# rCSL_sata_001 register map
Vendor: Texas Instruments
Registers are 32-bit, access not given, reset 0x0 unless marked. A register's access mark holds for its fields unless they carry their own. Offsets are as the file gives them; [hi:lo] are bit positions.

## SATA (part 2 of 2) — SATA Interface Controller
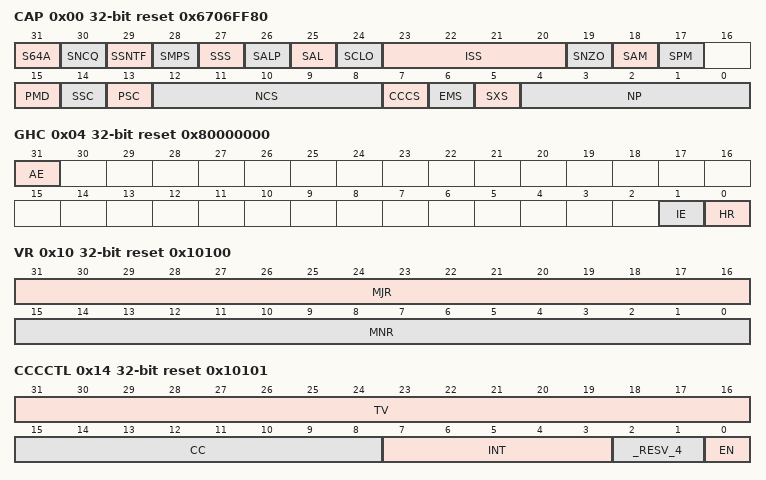
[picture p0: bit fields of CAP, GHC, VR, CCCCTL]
0x00 CAP reset 0x6706FF80 (reset mask 0xFF0FFFFF) — HBA Capabilities Register
  [31] S64A ro — Indicates the resolution of the addressing supported 32-bit or 64-bit. This bit field should always display 0 since only 32-bit addressing is supported. 0: 32-bit addressing is selected. 1: 64-bit addressing selected.
  [30] SNCQ ro — Indicates the support for Native Command Queueing. This bit field should always display 1 since Native Command Queueing is supported. 0: Native Command is not supported. 1: Native Command Queueing is supported by handlind DMA Setup FIS Natively.
  [29] SSNTF ro — Indicates Register SATASS support for SNotification. This bit field should always display 1 since SATASS suports POSNTF (SNotification) register and its asscoited functionality. 0: SNotification register and its associated functionality is not supported. 1: SNotification register and its associated functionality is supported.
  [28] SMPS rw — Indicates existence of a mechanical swich. Mechanical presence switch detection is supported by the SATASS. However, the visibility of the support for this switch is controlled by the Firmware with a one time write capability during power up time. Then after, this bit fied is read only. Firmware writes the following right after power-up: 0: Mechanical Switch is not present and no detecition capability is available. 1: Mechanical Switch is present and detection capability is available.
  [27] SSS rw — Indicates the supports for Staggered Spin-Up. Staggered Spin-Up is supported by the SATASS. However, the visibility of the support for this capability is controlled by the Firmware with a one time write capability during power up time.Then after, this bit field, is read-only. Firmware writes the following right after power-up: 0: Staggered Spin-Up is not supported. 1: Staggered Spin-Up is supported.
  [26] SALP ro — Indicates the support for Aggressive Link Power Manangemet (ALPM). This value should always display 1. 0: SATASS does not support ALPM. 1: SATASS supports ALPM.
  [25] SAL ro — Indicates the presence of activity. 0: No Activity 1: Activity is detected.
  [24] SCLO ro — Indicates the Support for the Command List Override. SATASS supports the P#CMD.CLO bit functionality for Port Multiplier Devices's Enumeration.
  [23:20] ISS ro — Indicates the maximum interface speed supported: Generation 1 which is 1.5 Gbps and Generation 2 which is 3.0 Gbps. 0: Reserved 1: 1.5 Gbps (Gen1) 2: 3.0 Gbps (Gen2) 3-15: Reserved
  [19] SNZO ro — Indicate the support the Non-Zero DMA Offsets. 0: Not Supported. 1: Non-Zero Offset supported.
  [18] SAM ro — Indicates whether the Legacy Task File Register Interface or AHCI interface supported. No support for Legacy Mode. 0: Task File Register Interface supported. 1: AHCI interface supported.
  [17] SPM ro — Indicates whether the support for Port Multiplier. 0: Command-based Switching Port Multiplier is not supported. 1: Command-based Switching Port Multiplier on any of its ports supported.
  [15] PMD ro — Indicates whether the support for PIO Multiple DRQ block data transfer is supported or not. 0: PIO Multiple DRQ block data transfer not supported. 1: PIO Multiple DRQ block data transfer supported.
  [14] SSC ro — Indicates whether the transition for the Slumber State Power Management Capability is supported or not. 0: Does not support the transition to the SLUMBER power state. 1: SATSS supports for the transition to the SLUMBER power state.
  [13] PSC ro — Indicates whether the transition capability to Partial power state management. 0: Does not support the transition to the PARTIAL power state. 1: SATSS supports the transition to the PARTIAL power state.
  [12:8] NCS ro — Indicates the number of command slots supported. The value encoded here is one less than the actual value, i.e. value of 0x1F implies the support for the maximum number of command slots per port, which is 32.
  [7] CCCS ro — Indicates if the Command Coalescing is supported or not. 0: Command Coalescing not supported. 1: Command Coalescing supported.
  [6] EMS ro — Indicates the support for Enclosure Management. 0: Enclosure Management not supported. 1: Enclosure Management is supported.
  [5] SXS ro — Indicates whether the support for External SATA is accomdated or not. 0: No External SATA is supported. 1: External SATA is supported.
  [4:0] NP ro — Indicates the number of SATA ports supported. Value encoded here is one less the actual value, i.e., value of 0 implies the support for a single 1 Port.
0x04 GHC reset 0x80000000 — Provides global functions for the SATASS
  [31] AE ro — Indicates the communication mechanism with the HBA being Legacy mode or Advanced Host Controller Interface mode. Since Legacy mode is not supported, the mode of communication is AHCI mode all the time, i.e, this bit field is always set. 0: AHCI is not enabled 1: AHCI is enabled.
  [1] IE rw — Global Interrupt Enable/Disable bit filed. This field is affected by HBA reset. 0: Interrupt is not Enabled globally. 1: Interrupt is Enabled globally.
  [0] HR wo — Host Bus Adaptor (HBA) reset. Only Write of '1' supported. When HBA is finished with the reset, it will clear this bit field to '0'. Write of '0' has no effect.
0x08 IS — Interrupt Status Register of a Port
  [0] IPS rw — Interrupt Pending Status for port 0. 0: No Pending Port 0 Interrupt. 1: Interrupt Pending for Port 0.
0x0C PI — Ports Implemented Register
  [0] PI ro — This bit field should be intialized by the Firmware, after power up, by writing '1' to it, since only one port is available and that is the minimum amount of port that should remain available. After the write by the Firmware, this bit field is read-only there after.
0x10 VR ro reset 0x10100 — This register indicates the version of the Synopsys AHCI core embedded in the SATASS.
  [31:16] MJR — Major Revision Number
  [15:0] MNR — Minor Revision Number
0x14 CCCCTL reset 0x10101 — This register is used to configure the command completion coalescing (CCC) feature for the SATASS core. It is reset on Global reset.
  [31:16] TV rw — Time out value recorded in 1ms interval. S/W should initialize/load this value prior to enabling CCC. Can only write to this field if CCCCTL.EN==0 (i.e. CCC is disabled). If not it is read only. The HBA will signal a CCC interrupt when the time out value entered has decremented to 0. A copy of this value is used within the HBA and this field value will not change. A value of 0x0000 is reserved and should not be used.
  [15:8] CC rw — Command Completions: This field specifies the number of command completions that are necessary to cause a CCC interrupt. S/W should initialize/load this value prior to enabling CCC. Can only write to this field if CCCCTL.EN==0 (i.e. CCC is disabled). If not it is read only. A value of 0x0000 is reserved and should not be used.
  [7:3] INT ro — This field specifies the interrupt used by the CCC feature and is meaningful in identifying the HBA port that has interrupt pending. Since the number or HBA port supported is one and the supported HBA port is port 0, this field is either 0 or 1. 0: No CCC feature interrupt pending. 1: CCC feature Interrupt is pending for HBA Port 0.
  [2:1] _RESV_4 — Resevered (access N)
  [0] EN rw — Enables/Disables CCC feature (note that some of the CCC fields require initialization prior to enabling CCC). 0: CCC feature is Disabled (no CCC interrupt will be generated). 1: CCC feature is Enabled (CCC interrupt may be generated based on timeout or command completion conditions).
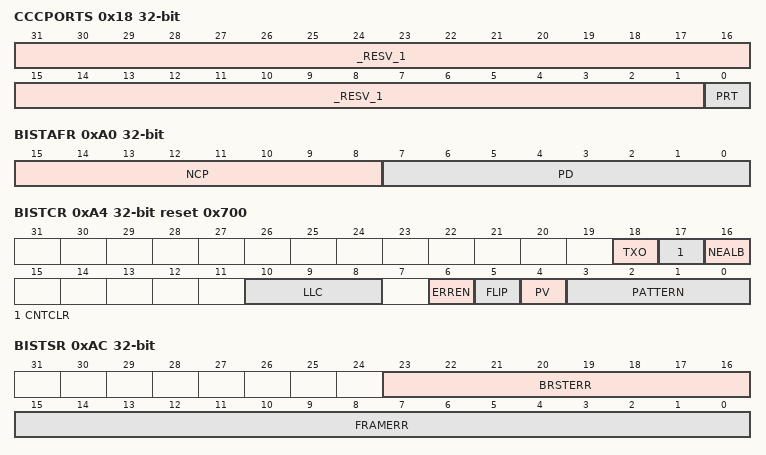
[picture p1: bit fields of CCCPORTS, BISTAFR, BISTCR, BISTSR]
0x18 CCCPORTS — This register specifies the Ports that are coalesced as part of the command completion coalescing (CCC) feature when CCC is enabled (i.e., CCCCTL.EN==1). It is reset on Global reset.
  [31:1] _RESV_1 — Resevered (access N)
  [0] PRT rw — Since the SATA SS incorporates a single HBA Port, only bit 0 of this register is meaningful. When enabling CCC feature, need to set this field to include HBA Port 0. 0: Port 0 is not part of the CCC feature. 1: Port 0 is part of the CCC feature.
0xA0 BISTAFR — BIST Active FIS Register
  [15:8] NCP ro — Non-Compliant Pattern. Least significant byte of the received BIST Activate FIS second DWORD (bits [7:0]). This value defines the required pattern for far-end transmit only mode (BISTAFR.PD=0x80 or 0xA0): " 0xF1 - Low transition density pattern (LTDP) " 0xB5 - High transition density pattern (HTDP) " 0xAB - Low frequency spectral component pattern (LFSCP) " 0x7F - Simultaneous switching outputs pattern (SSOP) " 0x8B - Lone Bit pattern (LBP) " 0x78 - Mid frequency test pattern (MFTP) " 0x4A - High frequency test pattern (HFTP) " 0x7E - Low frequency test pattern (LFTP) If none of these values is decoded, the simultaneous switching pattern is transmitted by default.
  [7:0] PD ro — Pattern Definition. Indicates the pattern definition field of the received BIST Activate FIS - bits [23:16] of the first DWORD. It is used to put the SATASS in one of the following BIST modes: " 0x10: Far-end retimed " 0x08: Far-end analog (if PHY supports this mode) " 0x80: Far-end transmit only " 0xA0: Far-end transmit only with scrambler bypassed All other values should not be used by the device, otherwise, the FIS will be negatively acknowledged with R_ERRp. For far-end transmit only modes BISTAFR.NCP field contains the required data pattern.
0xA4 BISTCR reset 0x700 — BIST Control Register
  [18] TXO wo — Transmit Only bit that is used to initate transmission of one of the non-compliant patterns defiend by the BISTCR[PATTERN] value when the device is disconnected.
  [17] CNTCLR wo — Clear error counter register. Clears BIST error count registers (BISTFCTR, BISTSR, and BISTDECR).
  [16] NEALB rw — Near-end Analog Loopback. This bit places the Port PHY into near-end analog loopback mode. Writing a 1 initiates a Near-end analog loopback request. BISTCR field contains the appropriate pattern. This mode should be initiated either in the PARTIAL or SLUMBER power mode, or with the device disconnected from the Port PHY (Link NOCOMM state). BIST Activate FIS is not sent to the device in this mode.
  [10:8] LLC rw — Link Layer Control. This field controls the Port Link Layer functions: scrambler, descrambler, and repeat primitive drop. Note the different meanings for normal and BIST modes of operation: Bit8 - SCRAM 0: Scrambler disabled in normal mode, enabled in BIST mode 1: Scrambler enabled in normal mode, disabled in BIST mode Bit9 - DESCRAM 0: Descrambler disabled in normal mode, enabled in BIST mode 1: Descrambler enabled in normal mode, disabled in BIST mode Bit10 - RPD 0: Repeat primitive drop function disabled in normal mode, enabled in BIST mode 1: Repeat primitive drop function enabled in normal mode, disabled in BIST mode
  [6] ERREN rw — Error Enable. This bit is used to allow or filter (disable) PHY internal errors outside the FIS boundary to set corresponding P#SERR bits: 0: Filter errors outside the FIS, allow errors inside the FIS 1: Allow errors outside or inside the FIS.
  [5] FLIP rw — Flip Disparity. This bit is used to change disparity of the current test pattern to the opposite every time its state is changed by software
  [4] PV rw — Pattern Version. This bit is used to select either short or long version of the SSOP, HTDP, LTDP, LFSCP, COMP patterns: 0: Short pattern version 1: Long pattern version
  [3:0] PATTERN rw — This field defines one of the following SATA compliant patterns for far-end retimed/ far-end analog/ near-end analog initiator modes, or non-compliant patterns for transmit-only responder mode when initiated by software writing to the BISTCR[TXO] bit. 0000: - Simultaneous switching outputs pattern (SSOP) 0001 - High transition density pattern (HTDP) 0010 - Low transition density pattern (LTDP) 0011 - Low frequency spectral component pattern (LFSCP) 0100 - Composite pattern (COMP) 0101 - Lone bit pattern (LBP) 0110 - Mid frequency test pattern (MFTP) 0111 - High frequency test pattern (HFTP) 1000 - Low frequency test pattern (LFTP) 1111 Reserved. Do Not Use
0xA8 BISTFCTR rw — BIST FIS Count Register. This register contains the received BIST FIS count in the loopback initiator far-end retimed, far-end analog and near-end analog modes.
  [31:0] BISTFCTR — Received BIST FIS Count. This register contains the received BIST FIS count in the loopback initiator far-end retimed, far-end analog and near-end analog modes. It is updated each time a new BIST FIS is received. It is reset by Global reset, Port reset (COMRESET) or by setting the BISTCR.CNTCLR bit. This register does not roll over and freezes when the FFFF_FFFFh value is reached. It takes approximately 65 hours of continuous BIST operation to reach this value.
0xAC BISTSR — BIST Status Register: This register contains errors detected in the received BIST FIS in the loopback initiator far-end retimed, far-end analog and near-end analog modes.
  [23:16] BRSTERR ro — Burst Error. This field contains the burst error count. It is accumulated each time a burst error condition is detected: DWORD error is detected in the received frame and 1.5 seconds (27,000 frames) passed since the previous burst error was detected. The BRSTERR value does not roll over and freezes at FFh. This field is updated if parameter BIST_MODE=DWORD. Do we require BIST_MODE=DWORD or FIS?
  [15:0] FRAMERR rw — Frame Error. This field contains the frame error count. It is accumulated (new value is added to the old value) each time a new BIST frame with a CRC error is received. The FRAMERR value does not roll over and freezes at FFFFh.
0xB0 BISTDECR ro — BIST DWORD Error Count Register.
  [31:0] DWERR — DWORD Error Count. This register contains the number of DWORD errors detected in the received BIST frame in the loopback initiator far-end retimed, far-end analog and near-end analog modes. It is updated each time a new BIST frame is received. It is reset by Global reset, Port reset (COMRESET) or by setting the BISTCR.CNTCLR bit. This register is updated only when the parameter BIST_MODE= DWORD . It is accumulated (new value is added to the old value) each time a new BIST frame is received. The DWERR value does not roll over and freezes if it exceeds 0xFFFF_F000.
0xE0 TIMER1MS reset 0x186A0 — This register is used to generate 1ms tick for the command completion coalescing (CCC) logic based on the AHB bus clock frequency.
  [19:0] TIMV — This register is used to generate 1ms tick for the command completion coalescing (CCC) logic based on the AHB bus clock frequency. Software must initialize this register with the required value after power up before using the CCC feature. This register is reset to 100,000d (TIMV value for 100Mhz hclk) on power up and is not affected by Global reset. That is for the internal timer to generate 1ms tick: vclk*1000 where vclk = vbus clock frequency in MHz. This field is: RW when CCC_CTL.EN==0 Read Only when CCC_CTL.EN==1
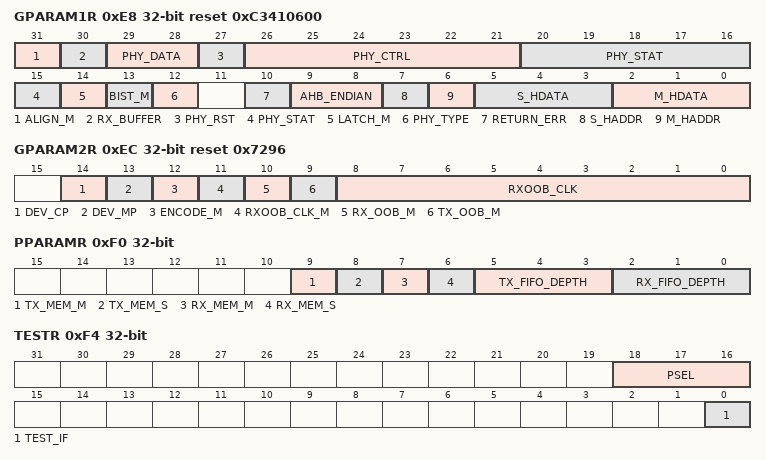
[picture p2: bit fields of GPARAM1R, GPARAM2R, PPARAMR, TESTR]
0xE8 GPARAM1R reset 0xC3410600 — This read-only register contains encoded information about the configuration of the embedded Synopsys AHCI SATA Core.
  [31] ALIGN_M ro — Rx Data Alignment: 0: Indicates Data is not aligned. 1: Indcates Data is always aligned.
  [30] RX_BUFFER ro — Rx Data Buffer. Core includes an Rx Data Buffer
  [29:28] PHY_DATA ro — PHY Data Width. 0: Data Width is 8 bits. 1-3: Reserved.
  [27] PHY_RST ro — PHY Reset Output Mode: 0: Indicates Output is Low. 1: Indicates Outupt is High.
  [26:21] PHY_CTRL ro — PHY Control Width. Indicates that there are 32-bits of PHY Control.
  [20:15] PHY_STAT ro — PHY Status Width. Indicates that the are 32-bits of PHY Status.
  [14] LATCH_M ro — Latch Mode. 0: SATASS does not include latches. 1: SATASS does include latches.
  [13] BIST_M ro — BIST Loopback Checking Depth. 0: Checks error per FIS.
  [12] PHY_TYPE ro — RHY Interface Incorporated Type. 0: TI PHY 1: Synopsys PHY
  [10] RETURN_ERR ro — AHB Error Response. 0: Indicates AHB Errors are not returned. 1: Indicates AHB Errors are returned.
  [9:8] AHB_ENDIAN ro — Bus Endianness. 0,1,3: Reserved. 2: Endian may be configured by Input Pin.
  [7] S_HADDR ro — Slave address bus width: 0: Indicates 32-bit Address Bus. 1: Indicates NONE 32-bit Address Bus.
  [6] M_HADDR ro — Master address bus width: 0: Indicates 32-bit Address Bus. 1: Indicates NONE 32-bit Address Bus.
  [5:3] S_HDATA ro — Slave data bus width: 0: Indicates 32-bit Data Bus. 1: Indicates NONE 32-bit Data Bus.
  [2:0] M_HDATA ro — Master data bus width: 0: Indicates 32-bit Data Bus. 1: Indicates NONE 32-bit Data Bus.
0xEC GPARAM2R reset 0x7296 — This read-only register contains additional encoded information about the configuration of the embedded Synopsys AHCI SATA Core.
  [14] DEV_CP ro — Cold Presence Detect feature Support. 0: Cold Presence Detect not supported. 1: Cold Presence Detect is supported.
  [13] DEV_MP ro — Mechanical Presence Switch Support. 0: Mechanical Presence Switch not supported. 1: Mechanical Presence Switch is supported.
  [12] ENCODE_M ro — 8b/10b Encoding Unit. 0: 8b/10b Encoding done outside Synopsys Core. 1: 8b/10b Encoding done inside Synopsys Core.
  [11] RXOOB_CLK_M ro — Rx OOB Clock Mode. Indicates 8b/10b encoding and decoding are done in the Synopsys core.
  [10] RX_OOB_M ro — Rx OOB Mode. 0: Indicates that Out-Of-Band signaling is done in the PHY. 1: Indicates that Out-Of-Band signaling is done by Synopsys Core.
  [9] TX_OOB_M ro — Tx OOB Mode. 0: Indicates that Out-Of-Band signaling is done in the PHY. 1: Indicates that Out-Of-Band signaling is done by the Synopsys core.
  [8:0] RXOOB_CLK ro — Rx OOB Clock Frequency. The value reflects the hexadecimal value of the RXOOB_CLK_FREQ parameter.
0xF0 PPARAMR — This read-only register contains encoded information about the configuration of the embedded Synopsys AHCI SATA Core.
  [9] TX_MEM_M ro — Tx FIFO Memory Read Port. Indicates that the Tx FIFO Memory is asynchronous read.
  [8] TX_MEM_S ro — Tx FIFO Memory Type. Indicates that the Tx FIFO memory is outside the the core (but still inside the sub-system wrapper).
  [7] RX_MEM_M ro — Rx FIFO Memory Read Port Type. Indicates that the Rx FIFO Memory is asynchronous read.
  [6] RX_MEM_S ro — Rx FIFO Memory Type. Indicates that the Rx FIFO memory is outside the the core (but still inside the sub-system wrapper).
  [5:3] TX_FIFO_DEPTH ro — Tx FIFO Depth. Indicates that the depth of the Tx FIFO is 32 DWORDS.
  [2:0] RX_FIFO_DEPTH ro — Rx FIFO Depth. Indicates that the depth of the Tx FIFO is 64 DWORDS.
0xF4 TESTR — This register is used to put the SATASS slave interface into a test mode and to select a Port for BIST operation.
  [18:16] PSEL rw — Port Select. This field is used to select the port for BIST operation. Note, there is only one port in this sub-system so 0x0 is the only legal value.
  [0] TEST_IF rw — Test Interface. This field is used to put the DWC SATA AHCI slave interface into test mode. 0: Normal Mode. The read back value of some registers is a function on the SATA AHCI state and will not match the value written. 1: Test Mode. The read back value of the registers will match the value written. Normal operation is disabled. The following registers can be accessed in this mode: - GHC register IE bit. - BISTAFR register NCP and PD bits become Read-Write. - BISTCR register LLC, ERREN, FLIP, PV, PATTERN. - BISTFCTR, BISTSR, BISTDECR become readwrite. - P0CLB/CLBU, P0FB/FBU registers. - P0IS register RW1C and UFS bits become readwrite. - P0IE register. - P0CMD register ASP, ALPE, DLAE, ATAPI, PMA bits. - P0TFD, P0SIG registers become read-write. - P0SCTL register; - P0SERR register RW1C bits become read-write bits. - P0SACT, P0CI, P0SNTF registers become readwrite. - P0DMACR register. - P0PHYCR register; - P0PHYSR register becomes read-write. Notes: 1. Interrupt is asserted if any of the IS register bits is set after setting the corresponding P0IS and P0IE registers and GHC.IE=1. 2. CAP.SMPS/SSS, PI, P0CMD.ESP/CPD/MPSP/ HPCP register bits are HwInit type and can not be used in test mode. They are written once after power-on reset and become read-only. 3. Global DWC SATA AHCI reset must be issued (GHC.HR=1) after TEST_IF bit is cleared following the Test mode operation.
0xF8 VERSIONR ro — This register contains the 32-bit SATASS Version
  [31:0] VERSION — Denotes the version of the SATASS.
0xFC IDR ro — This register contains the 32-bit SATASS ID
  [31:0] ID — Denotes the ID of SATASS
0x100 P0CLB rw — This register contain the 32-bit base address of the command list
  [31:0] CLB — Command List Base Address. This address is should be 1KByte Aligned bits[9:0] should be cleared to Zero.
0x108 P0FB rw — This register contain the 32-bit base address of the command list
  [31:0] FB — FIS Base Address. This address should be 256 bytes aligned.
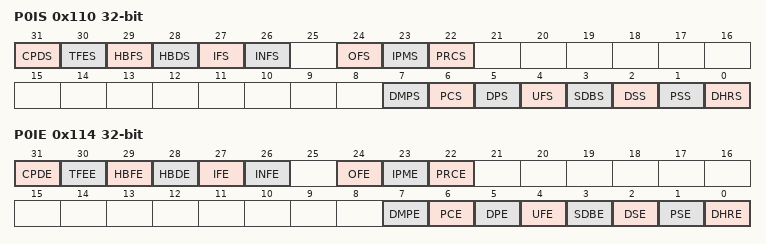
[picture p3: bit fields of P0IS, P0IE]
0x110 P0IS — This register is used to generate SATASS interrupts when any of the bits are set. Bits in this register are set by some internal conditions, and cleared by software writing ones in the positions it wants to clear.
  [31] CPDS rw — Cold Port Detect Status. When set, a device status has changed as detected by the cold presence detect logic. Write 1 to clear.
  [30] TFES rw — Task File Error Status. This bit is set whenever the P0TFD.STS register is updated by the device and error bit (bit 0) is set. Write 1 to clear.
  [29] HBFS rw — Host Bus Fatal Error Status. Indicates that the HBA encountered a host bus error that it cannot recover from, such as a bad software pointer. Write 1 to clear.
  [28] HBDS rw — Host Bus Data Error Status. Indicates that the HBA encountered a data error (uncorrectable ECC / parity) when reading from or writing to system memory. Write 1 to clear.
  [27] IFS rw — Interface Fata Error Status. Indicates that the HBA encountered an error on the Serial ATA interface which caused the transfer to stop. Write 1 to clear.
  [26] INFS rw — Interface Non-Fatal Error Status. Indicates that the HBA encountered an error on the Serial ATA interface but was able to continue operation. Write 1 to clear.
  [24] OFS rw — Overflow Status. Indicates that the HBA received more bytes from a device than was specified in the PRD table for the command. Write 1 to clear.
  [23] IPMS rw — Incorrect Port Multiplier Status. Indicates that the HBA received a FIS from a device whose Port Multiplier field did not match what was expected. Write 1 to clear.
  [22] PRCS rw — PHY Ready Change Status. When set to 1, indicates the internal PHY Ready signal changed state. This bit reflects the state of the P0SERR.DIAG_N bit. To clear this bit, the software must clear the P0SERR.DIAG_N bit to 0
  [7] DMPS rw — Device Mechanical Presence Status. When set, indicates that a mechanical presence switch attached to this port has been opened or closed, which may lead to a change in the connection state of the device. This bit is only valid if both CAP.SMPS and P0CMD.MPSP are set to 1 .
  [6] PCS rw — Port Connect Change Status. This bit reflects the state of the P0SERR.DIAG_X bit. This bit is only cleared when P0SERR.DIAG_X is cleared.
  [5] DPS rw — Descriptor Processed. A PRD with the I bit set has transferred all of its data.
  [4] UFS rw — Unknown FIS Interrupt. When set to 1, indicates that an unknown FIS was received and has been copied into system memory. This bit is cleared to 0 by software clearing the P0SERR.DIAG_F bit to 0.
  [3] SDBS rw — Set Device Bits Interrupts. A Set Device Bits FIS has been received with the I bit set and has been copied into system memory (Receive FIS).
  [2] DSS rw — DMA Setup FIS Interrupt. A DMA Setup FIS has been received with the 'I' bit set and has been copied into system memory (Receive FIS).
  [1] PSS rw — PIO Setup FIS Interrupt. A PIO Setup FIS has been received with the 'I' bit set and has been copied into system memory (Receive FIS), and the data related to that FIS has been transferred. This bit shall be set even if the data transfer resulted in an error.
  [0] DHRS rw — Device to Host Register FIS Interrupt. A D2H Register FIS has been received with the 'I' bit set and has been copied into system memory (Receive FIS).
0x114 P0IE — This register enables and disables the reporting of the corresponding interrupt to system software. When a bit is set ( 1 ) and the corresponding interrupt condition is active, then an interrupt is generated. Interrupt sources that are disabled ( 0 ) are still reflected in the status registers. This register is symmetrical with the P0IS register.
  [31] CPDE rw — Cold Port Detect Enable. When set, GHC.IE is set, and P0S.CPDS is set, the HBA shall generate an interrupt.
  [30] TFEE rw — Task File Error Status. When set, GHC.IE is set, and P0S.TFES is set, the HBA shall generate an interrupt
  [29] HBFE rw — Host Bus Fatal Error Enable. When set, GHC.IE is set, and P0IS.HBFS is set, the HBA shall generate an interrupt.
  [28] HBDE rw — Host Bus Data Error Status. when set, GHC.IE is set, and P0IS.HBDS is set, the HBA shall generate an interrupt..
  [27] IFE rw — Interface Fata Error Status. When set, GHC.IE is set, and P0IS.IFS is set, the HBA shall generate an interrupt..
  [26] INFE rw — Interface Non-Fatal Error Status. When set, GHC.IE is set, and P0IS.INFS is set, the HBA shall generate an interrupt.
  [24] OFE rw — Overflow Enable. When set, and GHC.IE and P0IS.OFS are set, the HBA shall generate an interupt
  [23] IPME rw — Incorrect Port Multiplier Enable. When set, and GHC.IE and P0IS.IPMS are set, the HBA shall generate an interupt.
  [22] PRCE rw — PHY Ready Change Enable. When set to 1 , and GHC.IE is set to 1 , and P0IS.PRCS is set to 1 , the HBA shall generate an interrupt.
  [7] DMPE rw — Device Mechanical Presence Enable.When set, and GHC.IE is set to 1 , and P0IS.DMPS is set, the HBA shall generate an interrupt.
  [6] PCE rw — Port Connect Change Enable.When set, GHC.IE is set, and P0IS.PCS is set, the HBA shall generate an interrupt
  [5] DPE rw — Descriptor Processed Interrupt Enable. When set, GHC.IE is set, and P0IS.DPS is set, the HBA shall generate an interrupt.
  [4] UFE rw — Unknown FIS Interrupt Enable.When set, GHC.IE is set, and P0IS.UFS is set to 1 , the HBA shall generate an interrupt.
  [3] SDBE rw — Set Device Bits Interrupt Enable.When set, GHC.IE is set, and P0IS.SDBS is set, the HBA shall generate an interrupt.
  [2] DSE rw — DMA Setup FIS Interrupt Enable.When set, GHC.IE is set, and P0IS.DSS is set, the HBA shall generate an interrupt.
  [1] PSE rw — PIO Setup FIS Interrupt Enable.When set, GHC.IE is set, and P0IS.PSS is set, the HBA shall generate an interrupt.
  [0] DHRE rw — Device to Host Register FIS Interrupt EnableWhen set, GHC.IE is set, and P0IS.DHRS is set, the HBA shall generate an interrupt.
